# R7FA0E209 register map
Vendor: Renesas Electronics Corporation; Series: RA0; File version: 1.00.00
CPU: CM23 r1p0, little endian, no MPU, no FPU, VTOR, 2 interrupt priority bits, 64 interrupts
Registers are 16-bit, read-write, reset 0x0 unless marked. A register's access mark holds for its fields unless they carry their own. Offsets are from the block's base; [hi:lo] are bit positions; {n}, {i} and the like mark numbered series; 'fields as' and 'values as' point back to an identical list.

## TAU — Timer Array Unit
Base 0x400A2600
{0x0+2i} TDR{i:02} (i=0..7) — Timer Data Register {i:02}
0x02 TDR01L 8-bit (alternate view of TDR01) — Timer Data Register 01
0x03 TDR01H 8-bit (alternate view of TDR01) — Timer Data Register 01
0x06 TDR03L 8-bit (alternate view of TDR03) — Timer Data Register 03
0x07 TDR03H 8-bit (alternate view of TDR03) — Timer Data Register 03
{0x100+2i} TCR0{i} (i=0..7) ro reset 0xFFFF — Timer Counter Register 0{i}
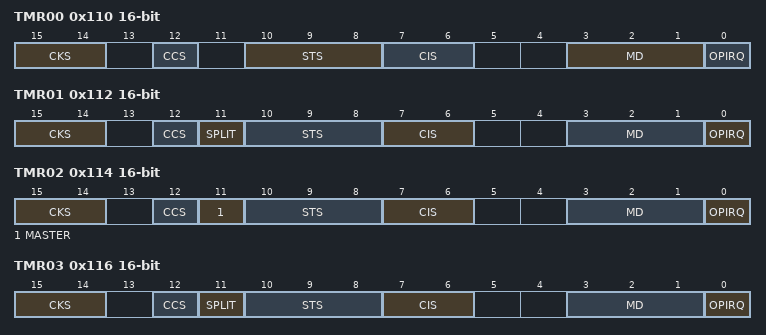
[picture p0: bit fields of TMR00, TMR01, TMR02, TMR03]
0x110 TMR00 — Timer Mode Register 00
  [15:14] CKS — Selection of Operation Clock (fMCK) of Channel 0
    0=Operation clock CK00 set by timer clock select register 0 (TPS0); 1=Operation clock CK02 set by timer clock select register 0 (TPS0); 2=Operation clock CK01 set by timer clock select register 0 (TPS0); 3=Operation clock CK03 set by timer clock select register 0 (TPS0)
  [12] CCS — Selection of Counter Clock (fTCLK) of Channel 0
    0=Operating clock (fMCK)specified by the CKS[1:0] bits; 1=Valid edge of input signal input from the TI00 pin. •In channel 5, valid edge of input signal selected by the TIS0 register •In channel 7, valid edge of input signal selected by the ISC register
  [10:8] STS — Setting of Start Trigger or Capture Trigger of Channel 0
    0=Only software trigger start is valid (other trigger sources are unselected); 1=Valid edge of the TI00 pin input is used as both the start trigger and capture trigger; 2=Both the edges of the TI00 pin input are used as a start trigger and a capture trigger; 4=Interrupt signal of the master channel is used (when the channel is used as a slave channel with the simultaneous channel operation function); other=Others (Setting prohibited)
  [7:6] CIS — Selection of TI00 Pin Input Valid Edge
    0=Falling edge; 1=Rising edge; 2=Both edges (when low-level width is measured) Start trigger: Falling edge, Capture trigger: Rising edge; 3=Both edges (when high-level width is measured) Start trigger: Rising edge, Capture trigger: Falling edge
  [3:1] MD — Selection of Operation Mode at Channel 0
    0=Interval timer mode; 2=Capture mode; 3=Event counter mode; 4=One-count mode; 6=Capture and one-count mode; other=Others (Setting prohibited)
  [0] OPIRQ — Setting of Starting Count and Interrupt
0x112 TMR01 — Timer Mode Register 01
  [15:14] CKS — Selection of Operation Clock (fMCK) of Channel 1
    values as TMR00.CKS
  [12] CCS — Selection of Counter Clock (fTCLK) of Channel 1
    0=Operating clock (fMCK) specified by the CKS[1:0] bits; 1=Valid edge of input signal input from the Ti01 pin In the case of unit 0: •In channel 5, valid edge of input signal selected by the TIS0 register •In channel 7, valid edge of input signal selected by the ISC register
  [11] SPLIT — Selection of 8 or 16-bit Timer Operation for Channels 1 and 3
    0=Operates as 16-bit timer (Operates in independent channel operation function or as slave channel in simultaneous channel operation function.); 1=Operates as 8-bit timer
  [10:8] STS — Setting of Start Trigger or Capture Trigger of Channel 1
    0=Only software trigger start is valid (other trigger sources are unselected); 1=Valid edge of the Ti01 pin input is used as both the start trigger and capture trigger; 2=Both the edges of the Ti01 pin input are used as a start trigger and a capture trigger; 4=Interrupt signal of the master channel is used (when the channel is used as a slave channel with the simultaneous channel operation function); other=Others (Setting prohibited)
  [7:6] CIS — Selection of TI01 Pin Input Valid Edge
    values as TMR00.CIS
  [3:1] MD — Selection of Operation Mode at Channel 1
    0=Interval timer mode; 2=Capture mode; 3=Event counter mode; 4=One-count mode; 6=Capture & one-count mode; other=Others (Setting prohibited)
  [0] OPIRQ — Setting of Starting Count and Interrupt
0x114 TMR02 — Timer Mode Register 02
  [15:14] CKS — Selection of Operation Clock (fMCK) of Channel 2
    values as TMR00.CKS
  [12] CCS — Selection of Counter Clock (fTCLK) of Channel 2
    0=Operating clock (fMCK)specified by the CKS[1:0] bits; 1=Valid edge of input signal input from the TI02 pin. •In channel 5, valid edge of input signal selected by the TIS0 register •In channel 7, valid edge of input signal selected by the ISC register
  [11] MASTER — Selection Between Using Channel 2 Independently or Simultaneously with Another Channel (as a Slave or Master)
    0=Operates in independent channel operation function or as slave channel in simultaneous channel operation function; 1=Operates as master channel in simultaneous channel operation function
  [10:8] STS — Setting of Start Trigger or Capture Trigger of Channel 2
    0=Only software trigger start is valid (other trigger sources are unselected); 1=Valid edge of the TI02 pin input is used as both the start trigger and capture trigger; 2=Both the edges of the TI02 pin input are used as a start trigger and a capture trigger; 4=Interrupt signal of the master channel is used (when the channel is used as a slave channel with the simultaneous channel operation function); other=Others (Setting prohibited)
  [7:6] CIS — Selection of TI02 Pin Input Valid Edge
    values as TMR00.CIS
  [3:1] MD — Selection of Operation Mode at Channel 2
    values as TMR00.MD
  [0] OPIRQ — Setting of Starting Count and Interrupt
0x116 TMR03 — Timer Mode Register 03
  [15:14] CKS — Selection of Operation Clock (fMCK) of Channel 3
    values as TMR00.CKS
  [12] CCS — Selection of Counter Clock (fTCLK) of Channel 3
    0=Operating clock (fMCK) specified by the CKS[1:0] bits; 1=Valid edge of input signal input from the Ti03 pin In the case of unit 0: •In channel 5, valid edge of input signal selected by the TIS0 register •In channel 7, valid edge of input signal selected by the ISC register
  [11] SPLIT — Selection of 8 or 16-bit Timer Operation for Channels 1 and 3
    values as TMR01.SPLIT
  [10:8] STS — Setting of Start Trigger or Capture Trigger of Channel 3
    0=Only software trigger start is valid (other trigger sources are unselected); 1=Valid edge of the Ti03 pin input is used as both the start trigger and capture trigger; 2=Both the edges of the Ti03 pin input are used as a start trigger and a capture trigger; 4=Interrupt signal of the master channel is used (when the channel is used as a slave channel with the simultaneous channel operation function); other=Others (Setting prohibited)
  [7:6] CIS — Selection of TI03 Pin Input Valid Edge
    values as TMR00.CIS
  [3:1] MD — Selection of Operation Mode at Channel 3
    values as TMR01.MD
  [0] OPIRQ — Setting of Starting Count and Interrupt
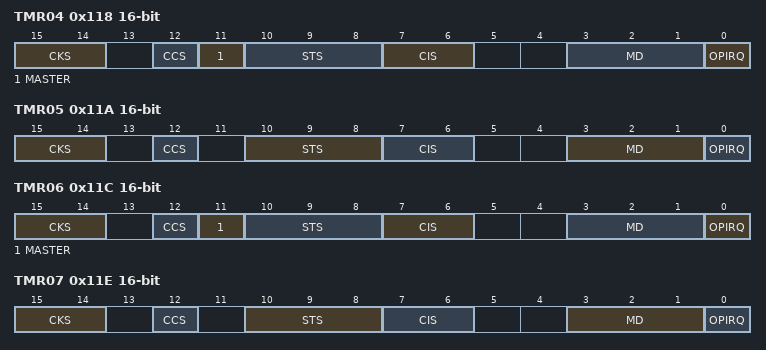
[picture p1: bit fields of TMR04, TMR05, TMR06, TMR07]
0x118 TMR04 — Timer Mode Register 04
  [15:14] CKS — Selection of Operation Clock (fMCK) of Channel 4
    values as TMR00.CKS
  [12] CCS — Selection of Counter Clock (fTCLK) of Channel 4
    0=Operating clock (fMCK)specified by the CKS[1:0] bits; 1=Valid edge of input signal input from the TI04 pin. •In channel 5, valid edge of input signal selected by the TIS0 register •In channel 7, valid edge of input signal selected by the ISC register
  [11] MASTER — Selection Between Using Channel 4 Independently or Simultaneously with Another Channel (as a Slave or Master)
    values as TMR02.MASTER
  [10:8] STS — Setting of Start Trigger or Capture Trigger of Channel 4
    0=Only software trigger start is valid (other trigger sources are unselected); 1=Valid edge of the TI04 pin input is used as both the start trigger and capture trigger; 2=Both the edges of the TI04 pin input are used as a start trigger and a capture trigger; 4=Interrupt signal of the master channel is used (when the channel is used as a slave channel with the simultaneous channel operation function); other=Others (Setting prohibited)
  [7:6] CIS — Selection of TI04 Pin Input Valid Edge
    values as TMR00.CIS
  [3:1] MD — Selection of Operation Mode at Channel 4
    values as TMR00.MD
  [0] OPIRQ — Setting of Starting Count and Interrupt
0x11A TMR05 — Timer Mode Register 05
  [15:14] CKS — Selection of Operation Clock (fMCK) of Channel 5
    values as TMR00.CKS
  [12] CCS — Selection of Counter Clock (fTCLK) of Channel 5
    0=Operating clock (fMCK)specified by the CKS[1:0] bits; 1=Valid edge of input signal input from the TI05 pin. •In channel 5, valid edge of input signal selected by the TIS0 register •In channel 7, valid edge of input signal selected by the ISC register
  [10:8] STS — Setting of Start Trigger or Capture Trigger of Channel 5
    0=Only software trigger start is valid (other trigger sources are unselected); 1=Valid edge of the TI05 pin input is used as both the start trigger and capture trigger; 2=Both the edges of the TI05 pin input are used as a start trigger and a capture trigger; 4=Interrupt signal of the master channel is used (when the channel is used as a slave channel with the simultaneous channel operation function); other=Others (Setting prohibited)
  [7:6] CIS — Selection of TI05 Pin Input Valid Edge
    values as TMR00.CIS
  [3:1] MD — Selection of Operation Mode at Channel 5
    values as TMR00.MD
  [0] OPIRQ — Setting of Starting Count and Interrupt
0x11C TMR06 — Timer Mode Register 06
  [15:14] CKS — Selection of Operation Clock (fMCK) of Channel 6
    values as TMR00.CKS
  [12] CCS — Selection of Counter Clock (fTCLK) of Channel 6
    0=Operating clock (fMCK)specified by the CKS[1:0] bits; 1=Valid edge of input signal input from the TI06 pin. •In channel 5, valid edge of input signal selected by the TIS0 register •In channel 7, valid edge of input signal selected by the ISC register
  [11] MASTER — Selection Between Using Channel 6 Independently or Simultaneously with Another Channel (as a Slave or Master)
    values as TMR02.MASTER
  [10:8] STS — Setting of Start Trigger or Capture Trigger of Channel 6
    0=Only software trigger start is valid (other trigger sources are unselected); 1=Valid edge of the TI06 pin input is used as both the start trigger and capture trigger; 2=Both the edges of the TI06 pin input are used as a start trigger and a capture trigger; 4=Interrupt signal of the master channel is used (when the channel is used as a slave channel with the simultaneous channel operation function); other=Others (Setting prohibited)
  [7:6] CIS — Selection of TI06 Pin Input Valid Edge
    values as TMR00.CIS
  [3:1] MD — Selection of Operation Mode at Channel 6
    values as TMR00.MD
  [0] OPIRQ — Setting of Starting Count and Interrupt
0x11E TMR07 — Timer Mode Register 07
  [15:14] CKS — Selection of Operation Clock (fMCK) of Channel 7
    values as TMR00.CKS
  [12] CCS — Selection of Counter Clock (fTCLK) of Channel 7
    0=Operating clock (fMCK)specified by the CKS[1:0] bits; 1=Valid edge of input signal input from the TI07 pin. •In channel 5, valid edge of input signal selected by the TIS0 register •In channel 7, valid edge of input signal selected by the ISC register
  [10:8] STS — Setting of Start Trigger or Capture Trigger of Channel 7
    0=Only software trigger start is valid (other trigger sources are unselected); 1=Valid edge of the TI07 pin input is used as both the start trigger and capture trigger; 2=Both the edges of the TI07 pin input are used as a start trigger and a capture trigger; 4=Interrupt signal of the master channel is used (when the channel is used as a slave channel with the simultaneous channel operation function); other=Others (Setting prohibited)
  [7:6] CIS — Selection of TI07 Pin Input Valid Edge
    values as TMR00.CIS
  [3:1] MD — Selection of Operation Mode at Channel 7
    values as TMR00.MD
  [0] OPIRQ — Setting of Starting Count and Interrupt
{0x120+2i} TSR0{i} (i=0..7) ro — Timer Status Register 0{i}
  [0] OVF — Counter Overflow State of Channel %s
    0=Overflow does not occur; 1=Overflow occurs
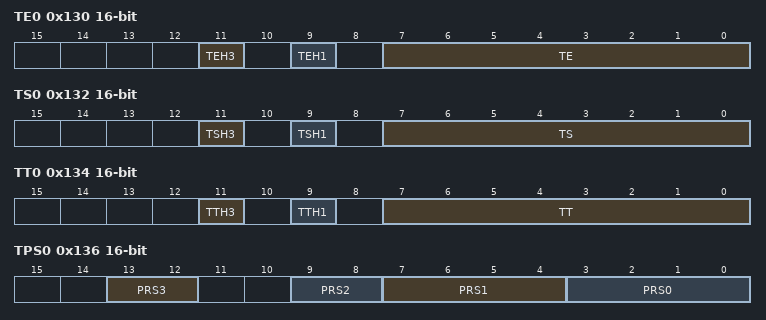
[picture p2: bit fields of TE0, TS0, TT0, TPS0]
0x130 TE0 ro — Timer Channel Enable Status Register 0
  [all] fields
    0=Operation is stopped; 1=Operation is enabled
  [11] TEH3 — Indication of whether Operation of the Higher 8-bit Timer is Enabled or Stopped when Channel 3 is in the 8-bit Timer Mode
  [9] TEH1 — Indication of whether Operation of the Higher 8-bit Timer is Enabled or Stopped when Channel 1 is in the 8-bit Timer Mode
  [7:0] TE — Indication of Operation Enabled or Stopped State of Channel n
0x132 TS0 — Timer Channel Start Register 0
  [11] TSH3 — Trigger to Enable Operation (Start Operation) of the Higher 8-bit Timer when Channel 3 is in the 8-bit Timer Mode
    0=No trigger operation; 1=The TE0.TEH3 bit is set to 1 and the count operation becomes enabled
  [9] TSH1 — Trigger to Enable Operation (Start Operation) of the Higher 8-bit Timer when Channel 1 is in the 8-bit Timer Mode
    0=No trigger operation; 1=The TE0.TEH1 bit is set to 1 and the count operation becomes enabled
  [7:0] TS — Operation Enable (Start) Trigger of Channel n
    0=No trigger operation; 1=The TE0.TE[n] bit is set to 1 and the count operation becomes enabled
0x134 TT0 — Timer Channel Stop Register 0
  [11] TTH3 — Trigger to Stop Operation of the Higher 8-bit Timer when Channel 3 is in the 8-bit Timer Mode
    0=No trigger operation; 1=The TE0.TEH3 bit is cleared to 0 and the count operation is stopped
  [9] TTH1 — Trigger to Stop Operation of the Higher 8-bit Timer when Channel 1 is in the 8-bit Timer Mode
    0=No trigger operation; 1=The TE0.TEH1 bit is cleared to 0 and the count operation is stopped
  [7:0] TT — Operation Stop Trigger of Channel n
    0=No trigger operation; 1=The TE0.TE[n] bit is cleared to 0 and the count operation is stopped
0x136 TPS0 — Timer Clock Select Register 0
  [13:12] PRS3 — Selection of Operation Clock (CK03)
    0=PCLKB/2^8; 1=PCLKB/2^10; 2=PCLKB/2^12; 3=PCLKB/2^14
  [9:8] PRS2 — Selection of Operation Clock (CK02)
    0=PCLKB/2; 1=PCLKB/2^2; 2=PCLKB/2^4; 3=PCLKB/2^6
  [7:4] PRS1 — Selection of Operation Clock (CK01)
    0=PCLKB; 1=PCLKB/2; {v}=PCLKB/2^{v} (v=2..15)
  [3:0] PRS0 — Selection of Operation Clock (CK00)
    0=PCLKB; 1=PCLKB/2; {v}=PCLKB/2^{v} (v=2..15)
0x138 TO0 — Timer Output Register 0
  [7:0] TO — Timer Output of Channel n
    0=Timer output value is 0; 1=Timer output value is 1
0x13A TOE0 — Timer Output Enable Register 0
  [7:0] TOE — Enabling or Disabling Timer Output for Channel n
    0=Disables timer output; 1=Enables timer output
0x13C TOL0 — Timer Output Level Register 0
  [7:1] TOL — Control of Timer Output of Channel n
    0=Positive logic output (active-high); 1=Negative logic output (active-low)
0x13E TOM0 — Timer Output Mode Register 0
  [7:1] TOM — Control of Timer Output Mode of Channel n
    0=Master channel output mode (to produce toggled output by timer interrupt request signal (TAU0_TMI0n)); 1=Slave channel output mode (output is set by the timer interrupt request signal (TAU0_TMI0n) of the master channel, and reset by the timer interrupt request signal (TAU0_TMI0p) of the slave channel)
